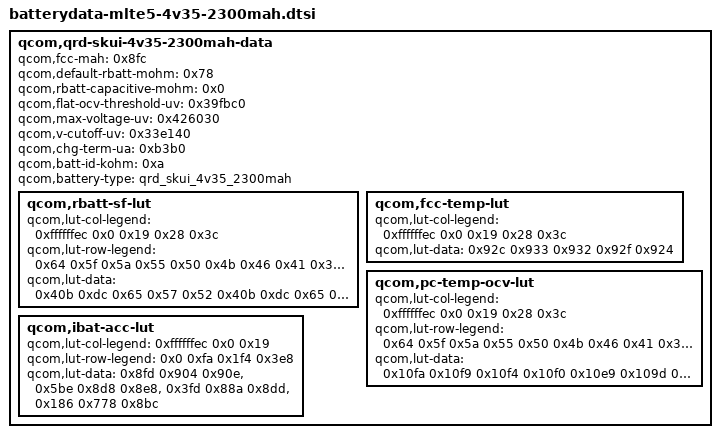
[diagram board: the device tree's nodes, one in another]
/* Copyright (c) 2015, The Linux Foundation. All rights reserved.
 *
 * This program is free software; you can redistribute it and/or modify
 * it under the terms of the GNU General Public License version 2 and
 * only version 2 as published by the Free Software Foundation.
 *
 * This program is distributed in the hope that it will be useful,
 * but WITHOUT ANY WARRANTY; without even the implied warranty of
 * MERCHANTABILITY or FITNESS FOR A PARTICULAR PURPOSE.  See the
 * GNU General Public License for more details.
 */

qcom,qrd-skui-4v35-2300mah-data {
		qcom,fcc-mah = <0x8fc>;
		qcom,default-rbatt-mohm = <0x78>;
		qcom,rbatt-capacitive-mohm = <0x0>;
		qcom,flat-ocv-threshold-uv = <0x39fbc0>;
		qcom,max-voltage-uv = <0x426030>;
		qcom,v-cutoff-uv = <0x33e140>;
		qcom,chg-term-ua = <0xb3b0>;
		qcom,batt-id-kohm = <0xa>;
		qcom,battery-type = "qrd_skui_4v35_2300mah";
		
qcom,rbatt-sf-lut {
		qcom,lut-col-legend = <0xffffffec 0x0 0x19 0x28 0x3c>;
		qcom,lut-row-legend = <0x64 0x5f 0x5a 0x55 0x50 0x4b 0x46 0x41 0x3c 0x37 0x32 0x2d 0x28 0x23 0x1e 0x19 0x14 0x10 0xd 0xb 0xa 0x9 0x8 0x7 0x6 0x5 0x4 0x3 0x2 0x1>;
		qcom,lut-data = <0x40b 0xdc 0x65 0x57 0x52 0x40b 0xdc 0x65 0x57 0x52 0x409 0xe4 0x66 0x57 0x52 0x401 0xe9 0x67 0x58 0x52 0x40a 0xf3 0x6b 0x59 0x53 0x3c7 0x102 0x70 0x5c 0x54 0x3a9 0xef 0x71 0x5f 0x56 0x3b4 0xe8 0x7b 0x63 0x58 0x3ad 0xe1 0x7f 0x69 0x5c 0x3aa 0xd9 0x73 0x66 0x5a 0x3c2 0xd6 0x66 0x58 0x54 0x3f4 0xd5 0x65 0x58 0x53 0x43a 0xd7 0x66 0x59 0x54 0x494 0xd9 0x66 0x5c 0x58 0x4f9 0xe3 0x68 0x5c 0x58 0x566 0xed 0x69 0x58 0x52 0x5ca 0xf2 0x67 0x58 0x52 0x619 0xee 0x67 0x59 0x53 0x644 0xf3 0x66 0x58 0x52 0x60c 0xf2 0x64 0x58 0x52 0x648 0xfc 0x65 0x58 0x53 0x686 0x104 0x67 0x5a 0x56 0x6c5 0x113 0x6c 0x5c 0x58 0x701 0x124 0x6e 0x5f 0x5a 0x749 0x135 0x72 0x61 0x5a 0x794 0x142 0x70 0x5c 0x58 0x82d 0x154 0x6d 0x5c 0x58 0x9fb 0x18b 0x72 0x62 0x5a 0xde6 0x1fe 0x7d 0x69 0x62 0x1bcd 0x3fc 0xf8 0xd2 0x82>;
	};

qcom,fcc-temp-lut {
		qcom,lut-col-legend = <0xffffffec 0x0 0x19 0x28 0x3c>;
		qcom,lut-data = <0x92c 0x933 0x932 0x92f 0x924>;
	};
	
qcom,pc-temp-ocv-lut {
		qcom,lut-col-legend = <0xffffffec 0x0 0x19 0x28 0x3c>;
		qcom,lut-row-legend = <0x64 0x5f 0x5a 0x55 0x50 0x4b 0x46 0x41 0x3c 0x37 0x32 0x2d 0x28 0x23 0x1e 0x19 0x14 0x10 0xd 0xb 0xa 0x9 0x8 0x7 0x6 0x5 0x4 0x3 0x2 0x1 0x0>;
		qcom,lut-data = <0x10fa 0x10f9 0x10f4 0x10f0 0x10e9 0x109d 0x10ac 0x10ae 0x10ac 0x10a8 0x1056 0x1070 0x1072 0x1070 0x106c 0x1018 0x103a 0x103a 0x1038 0x1034 0xfe6 0x1006 0x1006 0x1002 0xfff 0xf92 0xfda 0xfd8 0xfd2 0xfcd 0xf57 0xf88 0xf9b 0xfa0 0xfa0 0xf36 0xf60 0xf79 0xf7a 0xf77 0xf11 0xf3c 0xf52 0xf54 0xf51 0xeef 0xf19 0xf25 0xf28 0xf26 0xeda 0xefc 0xf00 0xf00 0xeff 0xeca 0xee5 0xee8 0xee8 0xee7 0xebe 0xed2 0xed6 0xed6 0xed4 0xeb3 0xec3 0xec8 0xec7 0xec5 0xea8 0xeba 0xebc 0xeb9 0xeb4 0xe9a 0xeae 0xeb0 0xea7 0xe9a 0xe8c 0xe9b 0xe9e 0xe94 0xe86 0xe7c 0xe87 0xe87 0xe7e 0xe71 0xe6d 0xe7c 0xe6f 0xe65 0xe5a 0xe61 0xe74 0xe68 0xe60 0xe54 0xe58 0xe72 0xe67 0xe5f 0xe53 0xe4e 0xe70 0xe66 0xe5e 0xe52 0xe44 0xe6c 0xe65 0xe5c 0xe51 0xe35 0xe67 0xe62 0xe5a 0xe4e 0xe21 0xe5c 0xe5d 0xe54 0xe45 0xe08 0xe46 0xe4a 0xe40 0xe2a 0xde6 0xe1c 0xe20 0xe11 0xdfe 0xdb5 0xdde 0xde2 0xdd4 0xdc1 0xd6a 0xd80 0xd8c 0xd7e 0xd6d 0xce7 0xce8 0xd04 0xcf8 0xced 0xbb8 0xbb8 0xbb8 0xbb8 0xbb8>;
	};

qcom,ibat-acc-lut {
		qcom,lut-col-legend = <0xffffffec 0x0 0x19>;
		qcom,lut-row-legend = <0x0 0xfa 0x1f4 0x3e8>;
		qcom,lut-data = <0x8fd 0x904 0x90e>,
				<0x5be 0x8d8 0x8e8>,
				<0x3fd 0x88a 0x8dd>,
				<0x186 0x778 0x8bc>;
		};
};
